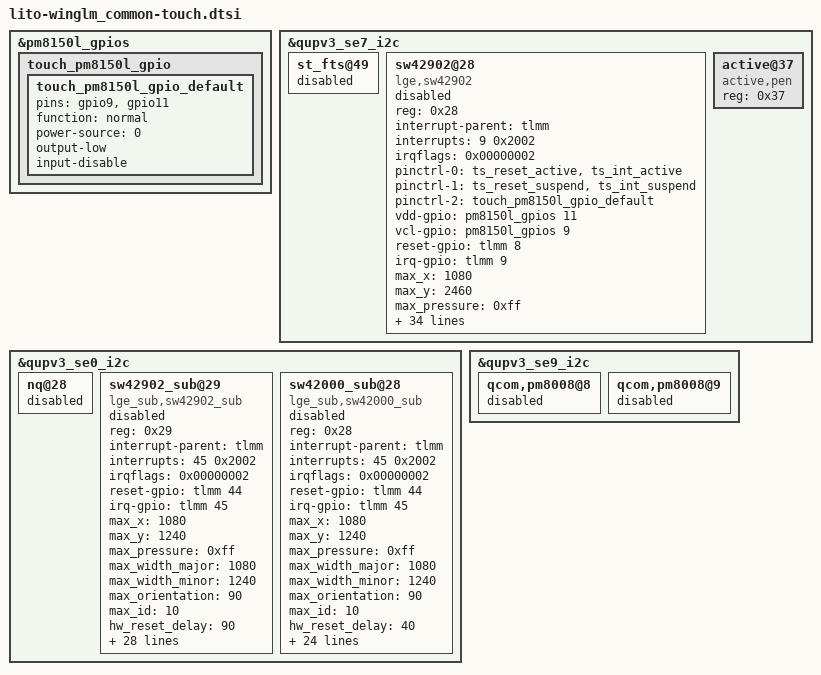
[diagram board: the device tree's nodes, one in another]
// SPDX-License-Identifier: GPL-2.0-only
/*
 * Copyright (c) 2018-2019, The Linux Foundation. All rights reserved.
 */

&pm8150l_gpios {
	touch_pm8150l_gpio{
		touch_pm8150l_gpio_default: touch_pm8150l_gpio_default {
			pins = "gpio9", "gpio11";
			function = "normal";
			power-source = <0>;
			output-low;
			input-disable;
		};
	};
};

&qupv3_se7_i2c {
	st_fts@49 {
		status = "disabled";
	};
	sw42902@28 {
		compatible = "lge,sw42902";
		reg = <0x28>;
		status = "disabled";
		interrupt-parent = <&tlmm>;
		interrupts = <9 0x2002>;
		irqflags = <0x00000002>;

		pinctrl-names = "touch_pin_active", "touch_pin_sleep", "touch_pm8150l_gpio_default";
		pinctrl-0 = <&ts_reset_active &ts_int_active>;
		pinctrl-1 = <&ts_reset_suspend &ts_int_suspend>;
		pinctrl-2 = <&touch_pm8150l_gpio_default>;

		vdd-gpio = <&pm8150l_gpios 11 0x00>;
		vcl-gpio = <&pm8150l_gpios 9 0x00>;
		reset-gpio = <&tlmm 8 0x00>;
		irq-gpio = <&tlmm 9 0x2002>;

		/* caps */
		max_x = <1080>;
		max_y = <2460>;
		max_pressure = <0xff>;
		max_width_major = <2460>;
		max_width_minor = <2460>;
		max_orientation = <90>;
		max_id = <10>;
		hw_reset_delay = <90>;
		sw_reset_delay = <10>;

		/* role */
		use_lpwg = <1>;
		use_lpwg_test = <1>;
		hide_coordinate = <1>;
		use_activepen_status = <1>;
		use_film_status = <1>;
		use_dex_mode = <1>;
		/* firmware */
		fw_image = "touch/winglm/B3W68WING_3_08.img",
					"touch/winglm/B3W68WING_0_15.img";

		panel_spec = "touch/winglm/wing_sw42902_limit.txt";
		panel_spec_mfts_folder = "touch/winglm/wing_sw42902_limit.txt";

		/* asc */
		use_asc = <0>;
		low_delta_thres = <350>;
		high_delta_thres = <600>;
		max_delta_cnt = <2>;

		/* Performance Test */
		use_perf_test = <1>;
		test_delay = <8>;
		test_pressure = <50>;
		test_width = <100>;
		click_test_x = <180>;
		click_test_y = <760>;
		v_drag_test_x = <144>;
		v_drag_test_start_y = <2003>;
		v_drag_test_end_y = <1116>;
		h_drag_test_start_x = <1163>;
		h_drag_test_end_x = <276>;
		h_drag_test_y = <2184>;
	};

	/* Temp Slave Address */
	active@37 {
		compatible = "active,pen";
		status = "ok";
		reg = <0x37>;
	};
};

&qupv3_se0_i2c {
	nq@28 {
		status = "disabled";
	};

	sw42902_sub@29 {
		compatible = "lge_sub,sw42902_sub";
		reg = <0x29>;
		status = "disabled";
		interrupt-parent = <&tlmm>;
		interrupts = <45 0x2002>;
		irqflags = <0x00000002>;

		reset-gpio = <&tlmm 44 0x00>;
		irq-gpio = <&tlmm 45 0x2002>;

		/* caps */
		max_x = <1080>;
		max_y = <1240>;
		max_pressure = <0xff>;
		max_width_major = <1080>;
		max_width_minor = <1240>;
		max_orientation = <90>;
		max_id = <10>;
		hw_reset_delay = <90>;
		sw_reset_delay = <10>;

		/* role */
		use_lpwg = <1>;
		use_lpwg_test = <1>;
		hide_coordinate = <1>;
		use_activepen_status = <0>;
		use_film_status = <1>;
		use_dex_mode = <1>;
		/* firmware */
		fw_image = "touch/winglm/B3W68DS3_5_06.img";

		panel_spec = "touch/winglm/wing_sw42902_limit.txt";
		panel_spec_mfts_folder = "touch/winglm/wing_sw42902_limit.txt";

		/* asc */
		use_asc = <0>;
		low_delta_thres = <350>;
		high_delta_thres = <600>;
		max_delta_cnt = <2>;

		/* Performance Test */
		use_perf_test = <1>;
		test_delay = <8>;
		test_pressure = <50>;
		test_width = <100>;
		click_test_x = <180>;
		click_test_y = <760>;
		v_drag_test_x = <144>;
		v_drag_test_start_y = <2003>;
		v_drag_test_end_y = <1116>;
		h_drag_test_start_x = <1163>;
		h_drag_test_end_x = <276>;
		h_drag_test_y = <2184>;
	};
	sw42000_sub@28 {
		status = "disabled";
		compatible = "lge_sub,sw42000_sub";

		reg = <0x28>;
		interrupt-parent = <&tlmm>;
		interrupts = <45 0x2002>;
		irqflags = <0x00000002>;

		reset-gpio = <&tlmm 44 0x00>;
		irq-gpio = <&tlmm 45 0x2002>;

		/* Caps */
		max_x = <1080>;
		max_y = <1240>;
		max_pressure = <0xff>;
		max_width_major = <1080>;
		max_width_minor = <1240>;
		max_orientation = <90>;
		max_id = <10>;
		hw_reset_delay = <40>;
		sw_reset_delay = <40>;

		/* role */
		use_lpwg = <1>;
		use_lpwg_test = <1>;
		hide_coordinate = <1>;
		use_activepen_status = <0>;
		use_film_status = <1>;
		use_dex_mode = <1>;

		/* Firmware */
		fw_image = "touch/winglm/V1W39WING_v0.18.img";
		panel_spec = "touch/winglm/wing_sw42000_limit.txt";
		panel_spec_mfts_folder = "touch/winglm/wing_sw42000_limit.txt";

		/* Performance Test */
		use_perf_test = <1>;
		test_delay = <8>;
		test_pressure = <50>;
		test_width = <100>;
		click_test_x = <180>;
		click_test_y = <838>;
		v_drag_test_x = <144>;
		v_drag_test_start_y = <2103>;
		v_drag_test_end_y = <1216>;
		h_drag_test_start_x = <1163>;
		h_drag_test_end_x = <276>;
		h_drag_test_y = <2284>;
	};

	/* Temp Slave Address */
/*
	active_sub@37 {
		compatible = "lge_sub,active_pen";
		status = "ok";
		reg = <0x37>;
	};
*/
};
&qupv3_se9_i2c {
	qcom,pm8008@8 {
		status = "disabled";
	};
};
&qupv3_se9_i2c {
	qcom,pm8008@9 {
		status = "disabled";
	};
};
